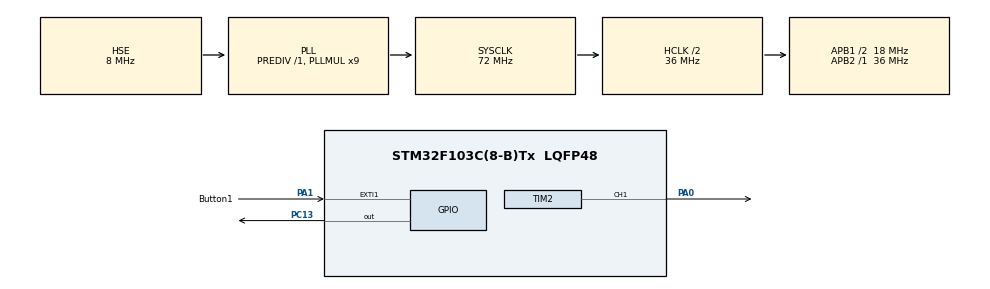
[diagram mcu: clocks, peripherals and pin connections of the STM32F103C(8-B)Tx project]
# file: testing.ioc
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Mcu.Family=STM32F1
Mcu.Name=STM32F103C(8-B)Tx
Mcu.Package=LQFP48
NVIC.EXTI1_IRQn=true\:0\:0\:false\:false\:true\:true\:true\:true
NVIC.PriorityGroup=NVIC_PRIORITYGROUP_4
NVIC.RCC_IRQn=true\:0\:0\:false\:false\:true\:true\:false\:true
NVIC.TIM1_UP_IRQn=true\:0\:0\:false\:false\:true\:true\:true\:true
NVIC.TIM2_IRQn=true\:0\:0\:false\:false\:true\:true\:true\:true
NVIC.TIM3_IRQn=true\:0\:0\:false\:false\:true\:true\:true\:true
PA0-WKUP.Signal=S_TIM2_CH1_ETR
PA1.GPIO_Label=Button1
PA1.GPIO_ModeDefaultEXTI=GPIO_MODE_IT_FALLING
PA1.GPIO_PuPd=GPIO_PULLUP
PA1.Signal=GPXTI1
PA13.Mode=Serial_Wire
PA13.Signal=SYS_JTMS-SWDIO
PA14.Mode=Serial_Wire
PA14.Signal=SYS_JTCK-SWCLK
PC13-TAMPER-RTC.Signal=GPIO_Output
PD0-OSC_IN.Mode=HSE-External-Oscillator
PD0-OSC_IN.Signal=RCC_OSC_IN
PD1-OSC_OUT.Mode=HSE-External-Oscillator
PD1-OSC_OUT.Signal=RCC_OSC_OUT
ProjectManager.HeapSize=0x200
ProjectManager.StackSize=0x400
ProjectManager.TargetToolchain=STM32CubeIDE
RCC.AHBCLKDivider=RCC_SYSCLK_DIV2
RCC.AHBFreq_Value=36000000
RCC.APB1CLKDivider=RCC_HCLK_DIV2
RCC.APB1Freq_Value=18000000
RCC.APB1TimFreq_Value=36000000
RCC.APB2Freq_Value=36000000
RCC.APB2TimFreq_Value=36000000
RCC.HCLKFreq_Value=36000000
RCC.PLLMUL=RCC_PLL_MUL9
RCC.PLLSourceVirtual=RCC_PLLSOURCE_HSE
RCC.SYSCLKFreq_VALUE=72000000
RCC.SYSCLKSource=RCC_SYSCLKSOURCE_PLLCLK
RCC.USBFreq_Value=72000000
SH.S_TIM2_CH1_ETR.0=TIM2_CH1,PWM Generation1 CH1
TIM1.Period=5000
TIM1.Prescaler=3600
TIM2.Channel-PWM\ Generation1\ CH1=TIM_CHANNEL_1
TIM2.Period=9025
TIM2.Prescaler=0
TIM2.Pulse-PWM\ Generation1\ CH1=2256
TIM3.Period=500
TIM3.Prescaler=3600
VP_TIM1_VS_ClockSourceINT.Mode=Internal
VP_TIM3_VS_ClockSourceINT.Mode=Internal
board=custom

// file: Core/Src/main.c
/* USER CODE BEGIN Header */
/**
  ******************************************************************************
  * @file           : main.c
  * @brief          : Main program body
  ******************************************************************************
  * @attention
  *
  * Copyright (c) 2024 STMicroelectronics.
  * All rights reserved.
  *
  * This software is licensed under terms that can be found in the LICENSE file
  * in the root directory of this software component.
  * If no LICENSE file comes with this software, it is provided AS-IS.
  *
  ******************************************************************************
  */
/* USER CODE END Header */
#include "main.h"

/* USER CODE BEGIN Includes */
#include "alarmTreashold.h"
#include "debounce.h"
/* USER CODE END Includes */

TIM_HandleTypeDef htim1;
TIM_HandleTypeDef htim2;
TIM_HandleTypeDef htim3;

/* USER CODE BEGIN PV */
volatile bool buttonPressed;
struct buttons button1 = {Button1_Pin, Button1_GPIO_Port, false, EXTI_FTSR_TR1, EXTI_RTSR_TR1};
struct buttons button2 = {Button1_Pin, Button1_GPIO_Port, false, EXTI_FTSR_TR1, EXTI_RTSR_TR1};
/* USER CODE END PV */

void SystemClock_Config(void);
static void MX_GPIO_Init(void);
static void MX_TIM1_Init(void);
static void MX_TIM2_Init(void);
static void MX_TIM3_Init(void);

/* USER CODE BEGIN 0 */

void HAL_GPIO_EXTI_Callback(uint16_t GPIO_Pin)
{
	if(GPIO_Pin == button1.pin)
	{
		callBackButton(&button1);
	}
	else if(GPIO_Pin == button2.pin)
	{
		callBackButton(&button2);
	}
	else
	{
		__NOP();
	}

}

/* USER CODE END 0 */

int main(void)
{

  /* MCU Configuration--------------------------------------------------------*/

  /* Reset of all peripherals, Initializes the Flash interface and the Systick. */
  HAL_Init();

  /* Configure the system clock */
  SystemClock_Config();

  /* Initialize all configured peripherals */
  MX_GPIO_Init();
  MX_TIM1_Init();
  MX_TIM2_Init();
  MX_TIM3_Init();
  /* USER CODE BEGIN 2 */
//HAL_TIM_Base_Start_IT(&htim1);
//HAL_TIM_PWM_Start_IT(&htim2, TIM_CHANNEL_1);

  /* USER CODE END 2 */

  /* Infinite loop */
  /* USER CODE BEGIN WHILE */
  while (1)
  {
	  //getDataFromButton();

    /* USER CODE END WHILE */

  }
}

void SystemClock_Config(void)
{
  RCC_OscInitTypeDef RCC_OscInitStruct = {0};
  RCC_ClkInitTypeDef RCC_ClkInitStruct = {0};

  /** Initializes the RCC Oscillators according to the specified parameters
  * in the RCC_OscInitTypeDef structure.
  */
  RCC_OscInitStruct.OscillatorType = RCC_OSCILLATORTYPE_HSE;
  RCC_OscInitStruct.HSEState = RCC_HSE_ON;
  RCC_OscInitStruct.HSEPredivValue = RCC_HSE_PREDIV_DIV1;
  RCC_OscInitStruct.HSIState = RCC_HSI_ON;
  RCC_OscInitStruct.PLL.PLLState = RCC_PLL_ON;
  RCC_OscInitStruct.PLL.PLLSource = RCC_PLLSOURCE_HSE;
  RCC_OscInitStruct.PLL.PLLMUL = RCC_PLL_MUL9;
  if (HAL_RCC_OscConfig(&RCC_OscInitStruct) != HAL_OK)
  {
    Error_Handler();
  }

  /** Initializes the CPU, AHB and APB buses clocks
  */
  RCC_ClkInitStruct.ClockType = RCC_CLOCKTYPE_HCLK|RCC_CLOCKTYPE_SYSCLK
                              |RCC_CLOCKTYPE_PCLK1|RCC_CLOCKTYPE_PCLK2;
  RCC_ClkInitStruct.SYSCLKSource = RCC_SYSCLKSOURCE_PLLCLK;
  RCC_ClkInitStruct.AHBCLKDivider = RCC_SYSCLK_DIV2;
  RCC_ClkInitStruct.APB1CLKDivider = RCC_HCLK_DIV2;
  RCC_ClkInitStruct.APB2CLKDivider = RCC_HCLK_DIV1;

  if (HAL_RCC_ClockConfig(&RCC_ClkInitStruct, FLASH_LATENCY_2) != HAL_OK)
  {
    Error_Handler();
  }
}

static void MX_TIM1_Init(void)
{

  TIM_ClockConfigTypeDef sClockSourceConfig = {0};
  TIM_MasterConfigTypeDef sMasterConfig = {0};

  htim1.Instance = TIM1;
  htim1.Init.Prescaler = 3600;
  htim1.Init.CounterMode = TIM_COUNTERMODE_UP;
  htim1.Init.Period = 5000;
  htim1.Init.ClockDivision = TIM_CLOCKDIVISION_DIV1;
  htim1.Init.RepetitionCounter = 0;
  htim1.Init.AutoReloadPreload = TIM_AUTORELOAD_PRELOAD_DISABLE;
  if (HAL_TIM_Base_Init(&htim1) != HAL_OK)
  {
    Error_Handler();
  }
  sClockSourceConfig.ClockSource = TIM_CLOCKSOURCE_INTERNAL;
  if (HAL_TIM_ConfigClockSource(&htim1, &sClockSourceConfig) != HAL_OK)
  {
    Error_Handler();
  }
  sMasterConfig.MasterOutputTrigger = TIM_TRGO_RESET;
  sMasterConfig.MasterSlaveMode = TIM_MASTERSLAVEMODE_DISABLE;
  if (HAL_TIMEx_MasterConfigSynchronization(&htim1, &sMasterConfig) != HAL_OK)
  {
    Error_Handler();
  }

}

static void MX_TIM2_Init(void)
{

  TIM_MasterConfigTypeDef sMasterConfig = {0};
  TIM_OC_InitTypeDef sConfigOC = {0};

  htim2.Instance = TIM2;
  htim2.Init.Prescaler = 0;
  htim2.Init.CounterMode = TIM_COUNTERMODE_UP;
  htim2.Init.Period = 9025;
  htim2.Init.ClockDivision = TIM_CLOCKDIVISION_DIV1;
  htim2.Init.AutoReloadPreload = TIM_AUTORELOAD_PRELOAD_DISABLE;
  if (HAL_TIM_PWM_Init(&htim2) != HAL_OK)
  {
    Error_Handler();
  }
  sMasterConfig.MasterOutputTrigger = TIM_TRGO_RESET;
  sMasterConfig.MasterSlaveMode = TIM_MASTERSLAVEMODE_DISABLE;
  if (HAL_TIMEx_MasterConfigSynchronization(&htim2, &sMasterConfig) != HAL_OK)
  {
    Error_Handler();
  }
  sConfigOC.OCMode = TIM_OCMODE_PWM1;
  sConfigOC.Pulse = 2256;
  sConfigOC.OCPolarity = TIM_OCPOLARITY_HIGH;
  sConfigOC.OCFastMode = TIM_OCFAST_DISABLE;
  if (HAL_TIM_PWM_ConfigChannel(&htim2, &sConfigOC, TIM_CHANNEL_1) != HAL_OK)
  {
    Error_Handler();
  }
  HAL_TIM_MspPostInit(&htim2);

}

static void MX_TIM3_Init(void)
{

  TIM_ClockConfigTypeDef sClockSourceConfig = {0};
  TIM_MasterConfigTypeDef sMasterConfig = {0};

  htim3.Instance = TIM3;
  htim3.Init.Prescaler = 3600;
  htim3.Init.CounterMode = TIM_COUNTERMODE_UP;
  htim3.Init.Period = 500;
  htim3.Init.ClockDivision = TIM_CLOCKDIVISION_DIV1;
  htim3.Init.AutoReloadPreload = TIM_AUTORELOAD_PRELOAD_DISABLE;
  if (HAL_TIM_Base_Init(&htim3) != HAL_OK)
  {
    Error_Handler();
  }
  sClockSourceConfig.ClockSource = TIM_CLOCKSOURCE_INTERNAL;
  if (HAL_TIM_ConfigClockSource(&htim3, &sClockSourceConfig) != HAL_OK)
  {
    Error_Handler();
  }
  sMasterConfig.MasterOutputTrigger = TIM_TRGO_RESET;
  sMasterConfig.MasterSlaveMode = TIM_MASTERSLAVEMODE_DISABLE;
  if (HAL_TIMEx_MasterConfigSynchronization(&htim3, &sMasterConfig) != HAL_OK)
  {
    Error_Handler();
  }

}

static void MX_GPIO_Init(void)
{
  GPIO_InitTypeDef GPIO_InitStruct = {0};

  /* GPIO Ports Clock Enable */
  __HAL_RCC_GPIOC_CLK_ENABLE();
  __HAL_RCC_GPIOD_CLK_ENABLE();
  __HAL_RCC_GPIOA_CLK_ENABLE();

  /*Configure GPIO pin Output Level */
  HAL_GPIO_WritePin(GPIOC, GPIO_PIN_13, GPIO_PIN_RESET);

  /*Configure GPIO pin : PC13 */
  GPIO_InitStruct.Pin = GPIO_PIN_13;
  GPIO_InitStruct.Mode = GPIO_MODE_OUTPUT_PP;
  GPIO_InitStruct.Pull = GPIO_NOPULL;
  GPIO_InitStruct.Speed = GPIO_SPEED_FREQ_LOW;
  HAL_GPIO_Init(GPIOC, &GPIO_InitStruct);

  /*Configure GPIO pin : Button1_Pin */
  GPIO_InitStruct.Pin = Button1_Pin;
  GPIO_InitStruct.Mode = GPIO_MODE_IT_FALLING;
  GPIO_InitStruct.Pull = GPIO_PULLUP;
  HAL_GPIO_Init(Button1_GPIO_Port, &GPIO_InitStruct);

  /* EXTI interrupt init*/
  HAL_NVIC_SetPriority(EXTI1_IRQn, 0, 0);
  HAL_NVIC_EnableIRQ(EXTI1_IRQn);

}

void Error_Handler(void)
{
  __disable_irq();
  while (1)
  {
  }
}
